# RE01_1500KB register map
Vendor: Renesas Electronics Corporation; Series: RE01_1500KB; File version: 1.20
CPU: CM0PLUS r0p1, little endian, MPU, no FPU, VTOR, 2 interrupt priority bits
Registers are 8-bit, read-write, reset 0x0 unless marked. A register's access mark holds for its fields unless they carry their own. Offsets are from the block's base; [hi:lo] are bit positions; lines under a group give offsets from that group; {n}, {i} and the like mark numbered series; 'fields as' and 'values as' point back to an identical list; <NAME> marks a mode.

## S14AD — 14bit A/D Converter
Base 0x4005C000
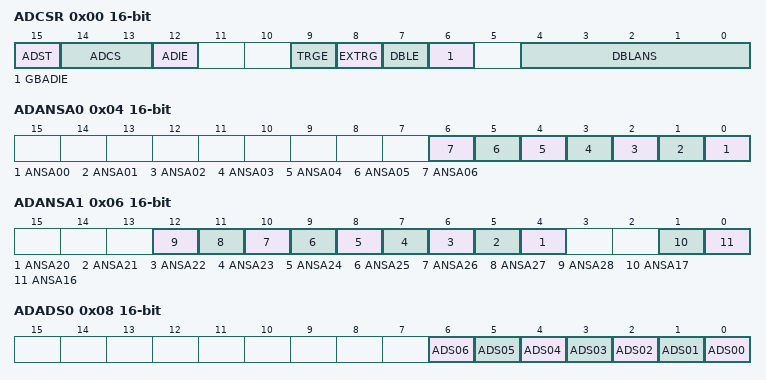
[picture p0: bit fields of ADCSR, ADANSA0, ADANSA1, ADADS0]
0x00 ADCSR 16-bit — A/D Control Register
  [15] ADST — A/D Conversion Start
    0=Stops A/D conversion process; 1=Starts A/D conversion process
  [14:13] ADCS — Scan Mode Select
    0=Single scan mode; 1=Group scan mode; 2=Continuous scan mode; 3=Setting prohibited
  [12] ADIE
  [9] TRGE — Trigger Start Enable
    0=Disables A/D conversion to be started by the synchronous or asynchronous trigger; 1=Enables A/D conversion to be started by the synchronous or asynchronous trigger
  [8] EXTRG — Trigger Select
    0=A/D conversion is started by the synchronous trigger (TMR,ELC); 1=A/D conversion is started by the asynchronous trigger (ADTRG0)
  [7] DBLE — Double Trigger Mode Select
    0=Double trigger mode non-selection; 1=Double trigger mode selection
  [6] GBADIE — Group B Scan End Interrupt Enable
    0=Disables ADC140_GBADI interrupt generation upon group B scan completion; 1=Enables ADC140_GBADI interrupt generation upon group B scan completion
  [4:0] DBLANS — Double Trigger Channel SelectThese bits select one analog input channel for double triggered operation. The setting is only effective while double trigger mode is selected.
0x04 ADANSA0 16-bit — A/D Channel Select Register A0
  [n] ANSA{n:02} (n=0..6) — AN{n:03} Select
    0=AN{n:03} is not subjected to conversion; 1=AN{n:03} is subjected to conversion
0x06 ADANSA1 16-bit — A/D Channel Select Register A1
  [n-16] ANSA{n} (n=20..28) — AN{n:04} Select
    0=AN{n:04} is not subjected to conversion; 1=AN{n:04} is subjected to conversion
  [1] ANSA17 — AN0017 Select
    0=AN0017 is not subjected to conversion; 1=AN0017 is subjected to conversion
  [0] ANSA16 — AN0016 Select
    0=AN0016 is not subjected to conversion; 1=AN0016 is subjected to conversion
0x08 ADADS0 16-bit — A/D-Converted Value Addition/Average Channel Select Register 0
  [n] ADS{n:02} (n=0..6) — A/D-Converted Value Addition/Average Channel AN{n:03} Select
    0=AN{n:03} is not selected; 1=AN{n:03} is selected
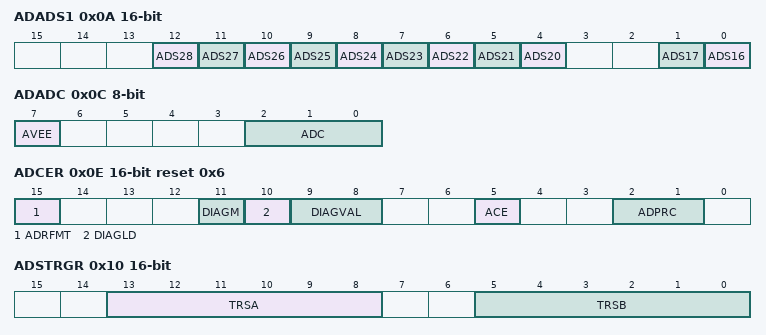
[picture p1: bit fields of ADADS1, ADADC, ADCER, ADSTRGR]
0x0A ADADS1 16-bit — A/D-Converted Value Addition/Average Channel Select Register 1
  [n-16] ADS{n} (n=20..28) — A/D-Converted Value Addition/Average Channel AN{n:03} Select
    0=AN{n:04} is not selected; 1=AN{n:04} is selected
  [1] ADS17 — A/D-Converted Value Addition/Average Channel AN017 Select
    0=AN0017 is not selected; 1=AN0017 is selected
  [0] ADS16 — A/D-Converted Value Addition/Average Channel AN016 Select
    0=AN0016 is not selected; 1=AN0016 is selected
0x0C ADADC — A/D-Converted Value Addition/Average Count Select Register
  [7] AVEE — Average Mode Enable
    0=Average mode is disabled*1; 1=Average mode is enabled*2
  [2:0] ADC — Addition frequency selection bit.
    0=1-time conversion (no addition; same as normal conversion); 1=2-time conversion (addition once); 3=4-time conversion (addition three times); 5=16-time conversion (addition 15 times), can not be set when selecting 14-bit accuracy; other=others (Setting prohibited)
0x0E ADCER 16-bit reset 0x6 — A/D Control Extended Register
  [15] ADRFMT — A/D Data Register Format Select
    0=Flush-right is selected for the A/D data register format; 1=Flush-left is selected for the A/D data register format
  [11] DIAGM — Self-Diagnosis Enable
    0=Disables self-diagnosis of A/D converter; 1=Enables self-diagnosis of A/D converter
  [10] DIAGLD — Self-Diagnosis Mode Select
    0=Rotation mode for self-diagnosis voltage; 1=Fixed mode for self-diagnosis voltage
  [9:8] DIAGVAL — Self-Diagnosis Conversion Voltage Select
    0=When the self-diagnosis fixation mode is selected, it set prohibits it; 1=The self-diagnosis by using the voltage of 0V; 2=The self-diagnosis by using the voltage of reference supply x 1/2; 3=The self-diagnosis by using the voltage of the reference supply
  [5] ACE — A/D Data Register Automatic Clearing Enable
    0=Disables automatic clearing; 1=Enables automatic clearing
  [2:1] ADPRC — A/D Conversion Accuracy Specify
    0=A/D conversion is performed with 12-bit accuracy; 3=A/D conversion is performed with 14-bit accuracy; other=others (Setting prohibited)
0x10 ADSTRGR 16-bit — A/D Conversion Start Trigger Select Register
  [13:8] TRSA — A/D Conversion Start Trigger SelectSelect the A/D conversion start trigger in single scan mode and continuous mode. In group scan mode, the A/D conversion start trigger for group A is selected.
  [5:0] TRSB — A/D Conversion Start Trigger Select for Group BSelect the A/D conversion start trigger for group B in group scan mode.
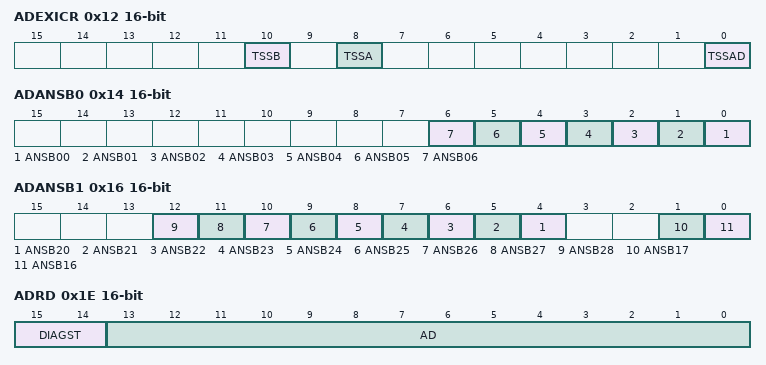
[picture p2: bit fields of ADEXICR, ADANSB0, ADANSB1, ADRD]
0x12 ADEXICR 16-bit — A/D Conversion Extended Input Control Register
  [10] TSSB — Temperature Sensor Output A/D Conversion Select for group B
    0=The temperature sensor output is not selected; 1=The temperature sensor output is selected
  [8] TSSA — Temperature Sensor Output A/D Conversion Select
    values as TSSB
  [0] TSSAD — Temperature Sensor Output A/D converted Value Addition/Average Mode Select
    0=Temperature sensor output A/D-converted value addition/average mode is not selected; 1=Temperature sensor output A/D-converted value addition/average mode is selected
0x14 ADANSB0 16-bit — A/D Channel Select Register B0
  [n] ANSB{n:02} (n=0..6) — AN{n:03} Select
    values as ADANSA0.ANSA00
0x16 ADANSB1 16-bit — A/D Channel Select Register B1
  [n-16] ANSB{n} (n=20..28) — AN{n:04} Select
    values as ADANSA1.ANSA20
  [1] ANSB17 — AN0017 Select
    values as ADANSA1.ANSA17
  [0] ANSB16 — AN0016 Select
    values as ADANSA1.ANSA16
0x18 ADDBLDR 16-bit ro — A/D Data Duplication Register
  [15:0] ADDBLDR — This is a 16-bit read-only register for storing the result of A/D conversion in response to the second trigger in double trigger mode.
0x1A ADTSDR 16-bit ro — A/D Temperature Sensor Data Register
  [15:0] ADTSDR — This is a 16-bit read-only register for storing the A/D conversion result of temperature sensor output.
0x1E ADRD 16-bit ro — A/D Self-Diagnosis Data Register
  [15:14] DIAGST — Self-Diagnosis StatusNote:Reference voltage refers to VREFH0.
    0=Self-diagnosis has never been executed since power-on; 1=Self-diagnosis using the voltage of 0 V has been executed; 2=Self-diagnosis using the voltage of reference power supply 1 x 1/2 has been executed; 3=Self-diagnosis using the voltage of reference power supply*1 has been executed
  [13:0] AD — A/D-converted value (right-justified)NOTE: Unused bits in the AD bit field are fixed 0
{0x20+2i} ADDR{i} (i=0..6) 16-bit ro — A/D Data Register {i}
  [15:0] ADDR — The ADDR register is a 16-bit read-only registers for storing the result of A/D conversion.
{0x20+2i} ADDR{i} (i=16..17) 16-bit ro — A/D Data Register {i}
  fields as ADDR0
{0x20+2i} ADDR{i} (i=20..28) 16-bit ro — A/D Data Register {i}
  fields as ADDR0
0x64 ADSCLKCR
  [0] SCLKEN
0x7A ADDISCR — A/D Disconnection Detection Control Register
  [4:0] ADNDIS — Disconnection Detection Assist SettingNOTE:When the A/D conversion of temperature sensor output is selected, ADNDIS[4:0] are set to 0Fh for discharging.
    0=Disconnection detection is disabled; 1=Setting prohibited; 2=2 cycle; {v}={v+1} cycle (v=3..15); 16=Disconnection detection is disabled; 17=Setting prohibited; 18=2 cycle; {v}={v-15} cycle (v=19..31)
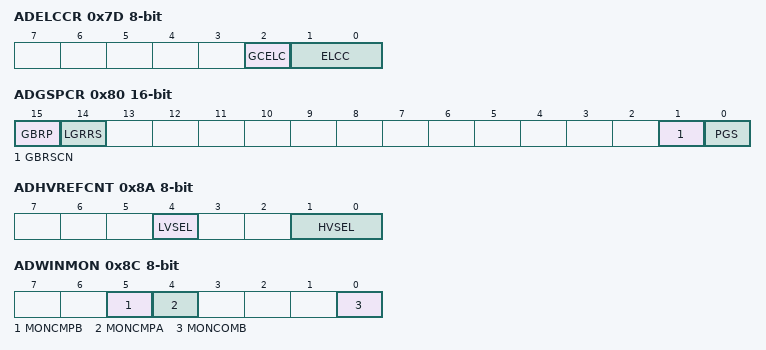
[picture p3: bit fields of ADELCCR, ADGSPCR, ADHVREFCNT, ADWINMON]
0x7D ADELCCR
  [2] GCELC — Group C Event Link Control
    0=No event is generated when group C scan completes in groupscan; 1=An event is generated when group C scan completes in groupscan
  [1:0] ELCC — Event Link Control
    0=An event is generated upon completion of scanning other; 1=An event is generated when group B scan completes in; other=others (An event is generated)
0x80 ADGSPCR 16-bit — A/D Group Scan Priority Control Register
  [15] GBRP — Single Scan Continuous Start(Enabled only when PGS = 1. Reserved when PGS = 0.)Note: When the GBRP bit has been set to 1, single scan is performed continuously for the lowest priority group regardless of the setting of the GBRSCN bit.
    0=Single scan is not continuously activated; 1=Single scan is continuously activated for the lowest priority group
  [14] LGRRS
  [1] GBRSCN — Low priority group Restart Setting(Enabled only when PGS = 1. Reserved when PGS = 0.)
    0=Scanning for low priority group is not restarted after having been discontinued due to priority control; 1=Scanning for low priority group is restarted after having been discontinued due to priority control
  [0] PGS — Group priority control setting bit.Note: When the PGS bit is to be set to 1, the ADCSR.ADCS[1:0] bits must be set to 01b (group scan mode). If the bits are set to any other values, proper operation is not guaranteed.
    0=Operation is without priority control; 1=Operation is with priority control
0x8A ADHVREFCNT — A/D High-Potential/Low-Potential Reference Voltage Control Register
  [4] LVSEL — Low-Potential Reference Voltage Select
    0=Select AVSS0 as the low-potential reference voltage; 1=Select VREFL0 as the low-potential reference voltage
  [1:0] HVSEL — High-Potential Reference Voltage Select
    0=Select AVCC0 as the high-potential reference voltage; 1=Select VREFH0 as the high-potential reference voltage; other=others (Setting prohibited)
0x8C ADWINMON ro — A/D Compare Function Window A/B Status Monitor Register
  [5] MONCMPB — Comparison Result Monitor B
    0=Window B comparison conditions are not met; 1=Window B comparison conditions are met
  [4] MONCMPA — Comparison Result Monitor A
    0=Window A comparison conditions are not met; 1=Window A comparison conditions are met
  [0] MONCOMB — Combination result monitorThis bit indicates the combination result.This bit is valid when both window A operation and window B operation are enabled.
    0=Window A / window B composite conditions are not met; 1=Window A / window B composite conditions are met
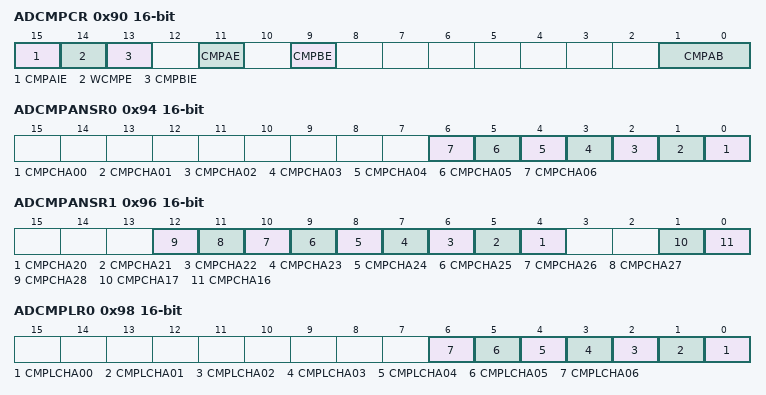
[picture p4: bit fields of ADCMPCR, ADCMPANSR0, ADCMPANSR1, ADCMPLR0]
0x90 ADCMPCR 16-bit — A/D Compare Function Control Register
  [15] CMPAIE — Compare A Interrupt Enable
    0=ADC140_CMPAI interrupt is disabled when comparison conditions (window A) are met; 1=ADC140_CMPAI interrupt is enabled when comparison conditions (window A) are met
  [14] WCMPE — Window Function Setting
    0=Window function is disabled. Window A and window B operate as a comparator to comparator the single value on the lower side with the A/D conversion result.; 1=Window function is enabled. Window A and window B operate as a comparator to comparator the two values on the upper and lower sides with the A/D conversion result.
  [13] CMPBIE — Compare B Interrupt Enable
    0=ADC140_CMPBI interrupt is disabled when comparison conditions (window B) are met; 1=ADC140_CMPBI interrupt is enabled when comparison conditions (window B) are met
  [11] CMPAE — Compare Window A Operation Enable
    0=Compare window A operation is disabled. ADC140_WCMPM and ADC140_WCMPUM outputs are disabled.; 1=Compare window A operation is enabled
  [9] CMPBE — Compare Window B Operation Enable
    0=Compare window B operation is disabled. ADC140_WCMPM and ADC140_WCMPUM outputs are disabled.; 1=Compare window B operation is enabled
  [1:0] CMPAB — Window A/B Composite Conditions SettingNOTE: These bits are valid when both window A and window B are enabled (CMPAE = 1 and CMPBE = 1).
    0=ADC140_WCMPM is output when window A comparison conditions are met OR window B comparison conditions are met. ADC140_WCMPUM is output in other cases.; 1=ADC140_WCMPM is output when window A comparison conditions are met EXOR window B comparison conditions are met. ADC140_WCMPUM is output in other cases.; 2=ADC140_WCMPM is output when window A comparison conditions are met and window B comparison conditions are met. ADC140_WCMPUM is output in other cases.; 3=Setting prohibited
0x92 ADCMPANSER — A/D Compare Function Window A Extended Input Select Register
  [0] CMPTSA — Temperature sensor output Compare selection bit.
    0=Excludes the temperature sensor output from the compare window A target range; 1=Includes the temperature sensor output in the compare window A target range
0x93 ADCMPLER — A/D Compare Function Window A Extended Input Comparison Condition Setting Register
  [0] CMPLTSA — Compare Window A Temperature Sensor Output Comparison Condition Select
    0=ADCMPDR0 register value > A/D-converted value(ADCMPCR.WCMPE=0) / AD-converted value < ADCMPDR0 register value or A/D-converted value > ADCMPDR1 register value(ADCMPCR.WCMPE=1); 1=ADCMPDR0 register value < A/D-converted value(ADCMPCR.WCMPE=0) / ADCMPDR0 register value < A/D-converted value < ADCMPDR1 register value(ADCMPCR.WCMPE=1)
0x94 ADCMPANSR0 16-bit — A/D Compare Function Window A Channel Select Register 0
  [n] CMPCHA{n:02} (n=0..6) — AN{n:03} Select
    0=Excludes AN{n:03} from the compare window A target range; 1=Includes AN{n:03} from the compare window A target range
0x96 ADCMPANSR1 16-bit — A/D Compare Function Window A Channel Select Register 1
  [n-16] CMPCHA{n} (n=20..28) — AN{n:04} Select
    0=Excludes AN{n:04} from the compare window A target range; 1=Includes AN{n:04} from the compare window A target range
  [1] CMPCHA17 — AN0017 Select
    0=Excludes AN0017 from the compare window A target range; 1=Includes AN0017 from the compare window A target range
  [0] CMPCHA16 — AN0016 Select
    0=Excludes AN0016 from the compare window A target range; 1=Includes AN0016 from the compare window A target range
0x98 ADCMPLR0 16-bit — A/D Compare Function Window A Comparison Condition Setting Register 0
  [all] fields
    0=ADCMPDR0 value > A/D converted value (ADCMPCR.WCMPE=0) / A/D converted value < ADCMPDR0 value or, ADCMPDR1 value < A/D converted value (ADCMPCR.WCMPE=1); 1=ADCMPDR0 value < A/D converted value (ADCMPCR.WCMPE=0) / A/DCMPDR0 value < A/D converted value < ADCMPDR1 value (ADCMPCR.WCMPE=1)
  [n] CMPLCHA{n:02} (n=0..6) — Comparison condition of AN{n:03}
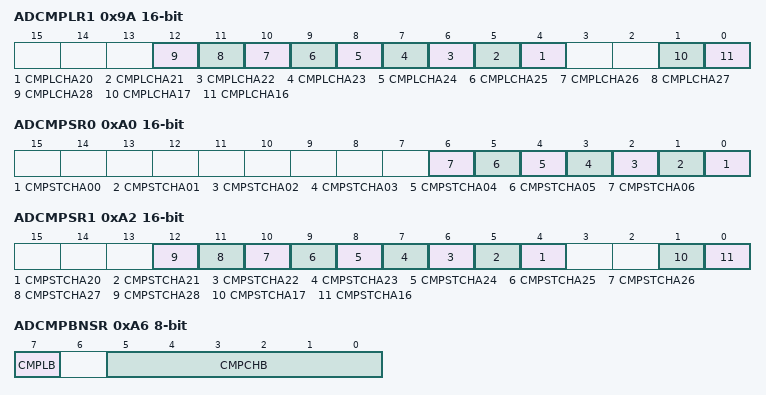
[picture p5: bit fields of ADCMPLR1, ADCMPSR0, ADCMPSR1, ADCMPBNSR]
0x9A ADCMPLR1 16-bit — A/D Compare Function Window A Comparison Condition Setting Register 1
  [all] fields
    values as the fields of ADCMPLR0
  [n-16] CMPLCHA{n} (n=20..28) — Comparison condition of AN{n:04}
  [1] CMPLCHA17 — Comparison condition of AN0017
  [0] CMPLCHA16 — Comparison condition of AN0016
0x9C ADCMPDR0 16-bit — A/D Compare Function Window A Lower-Side Level Setting Register
  [15:0] ADCMPDR0 — The ADCMPDR0 register sets the reference data when the compare window A function is used. ADCMPDR0 sets the lower-side level of window A.
0x9E ADCMPDR1 16-bit — A/D Compare Function Window A Upper-Side Level Setting Register
  [15:0] ADCMPDR1 — The ADCMPDR1 register sets the reference data when the compare window A function is used. ADCMPDR1 sets the upper-side level of window A..
0xA0 ADCMPSR0 16-bit — A/D Compare Function Window A Channel Status Register 0
  [all] fields
    0=Comparison conditions are not met; 1=Comparison conditions are met
  [n] CMPSTCHA{n:02} (n=0..6) — Compare window A flag of AN{n:03}
0xA2 ADCMPSR1 16-bit — A/D Compare Function Window A Channel Status Register 1
  [all] fields
    values as the fields of ADCMPSR0
  [n-16] CMPSTCHA{n} (n=20..28) — Compare window A flag of AN{n:04}
  [1] CMPSTCHA17 — Compare window A flag of AN0017
  [0] CMPSTCHA16 — Compare window A flag of AN0016
0xA4 ADCMPSER — A/D Compare Function Window A Extended Input Channel Status Register
  [0] CMPSTTSA — Compare Window A Temperature Sensor Output Compare Flag When window A operation is enabled (ADCMPCR.CMPAE = 1b), this bit indicates the temperature sensor output comparison result.
    values as the fields of ADCMPSR0
0xA6 ADCMPBNSR — A/D Compare Function Window B Channel Selection Register
  [7] CMPLB — Compare window B Compare condition setting bit.
    0=CMPLLB value > A/D converted value (ADCMPCR.WCMPE=0) / A/D converted value < CMPLLB value or CMPULB value > A/D converted value (ADCMPCR.WCMPE=1); 1=CMPLLB value < A/D converted value(ADCMPCR.WCMPE=0) / CMPLLB value < A/D converted value < CMPULB value (ADCMPCR.WCMPE=1)
  [5:0] CMPCHB — Compare window B channel selection bit.The channel that compares it on the condition of compare window B is selected.
    {v}=AN{v:03} (v=0..6); {v}=AN{v+9:03} (v=7..13); {v}=AN{v+9:03} (v=16..19); 32=Temperature sensor; 63=No channel is selected; other=others (Setting prohibited)
0xA8 ADWINLLB 16-bit — A/D Compare Function Window B Lower-Side Level Setting Register
  [15:0] ADWINLLB — This register is used to compare A window function is used to set the lower level of the window B.
0xAA ADWINULB 16-bit — A/D Compare Function Window B Upper-Side Level Setting Register
  [15:0] ADWINULB — This register is used to compare A window function is used to set the higher level of the window B.
0xAC ADCMPBSR — A/D Compare Function Window B Status Register
  [0] CMPSTB — Compare window B flag.It is a status flag that shows the comparative result of CH (AN000-AN019 and temperature sensor) made the object of window B relation condition.
    values as the fields of ADCMPSR0
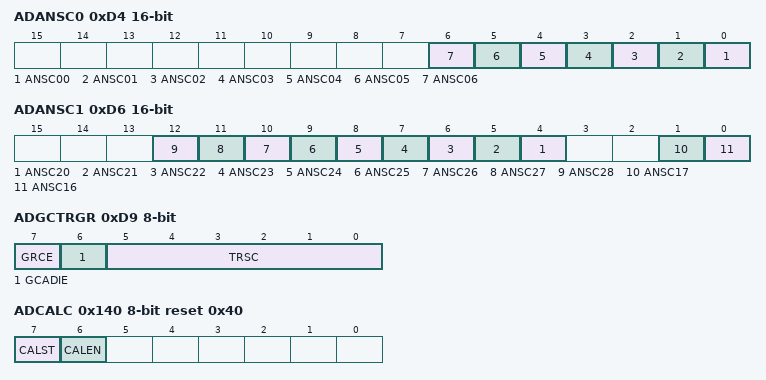
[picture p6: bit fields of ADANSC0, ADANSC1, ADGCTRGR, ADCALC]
0xD4 ADANSC0 16-bit — A/D Channel Select Register C0
  [n] ANSC{n:02} (n=0..6) — AN{n:03} Select
    values as ADANSA0.ANSA00
0xD6 ADANSC1 16-bit — A/D Channel Select Register C1
  [n-16] ANSC{n} (n=20..28) — AN{n:04} Select
    values as ADANSA1.ANSA20
  [1] ANSC17 — AN0017 Select
    values as ADANSA1.ANSA17
  [0] ANSC16 — AN0016 Select
    values as ADANSA1.ANSA16
0xD8 ADGCEXCR
  [0] TSSC
0xD9 ADGCTRGR
  [7] GRCE
  [6] GCADIE
  [5:0] TRSC
    63=111111; 11=001011
0xDD ADSSTRL reset 0xF — A/D Sampling State Register L
  [7:0] SST range 0x05..0xFF — Sampling Time Setting (AN016-AN019)
0xDE ADSSTRT reset 0xF — A/D Sampling State Register T
  [7:0] SST range 0x05..0xFF — Sampling Time Setting (temperature sensor output)
{0xE0+i} ADSSTR{i} (i=0..6) reset 0xF — A/D Sampling State Register {i}
  [7:0] SST range 0x05..0xFF — Sampling time setting
0x140 ADCALC reset 0x40
  [7] CALST, [6] CALEN
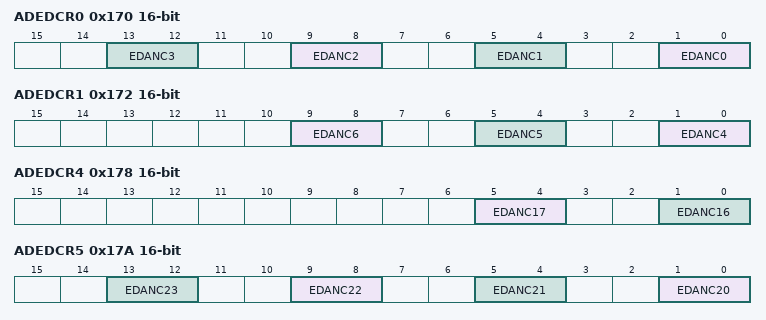
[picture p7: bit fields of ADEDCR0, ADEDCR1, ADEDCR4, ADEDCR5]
0x170 ADEDCR0 16-bit
  [all] fields
    0=00; 1=01; 2=10; 3=11
  [4n+1:4n] EDANC{n} (n=0..3)
0x172 ADEDCR1 16-bit
  [all] fields
    0=00; 1=01; 2=10; 3=11
  [9:8] EDANC6
  [5:4] EDANC5
  [1:0] EDANC4
0x178 ADEDCR4 16-bit
  [5:4] EDANC17
    0=00; 1=01; 2=10; 3=11
  [1:0] EDANC16
    0=00; 1=01; 2=10; 3=11
0x17A ADEDCR5 16-bit
  [all] fields
    0=00; 1=01; 2=10; 3=11
  [4n-79:4n-80] EDANC{n} (n=20..23)
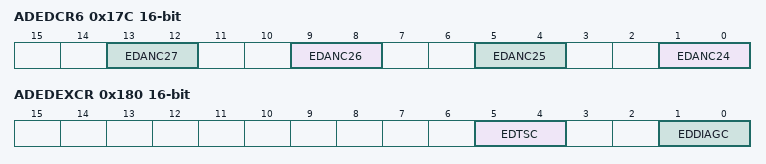
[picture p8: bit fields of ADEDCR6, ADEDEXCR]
0x17C ADEDCR6 16-bit
  [all] fields
    0=00; 1=01; 2=10; 3=11
  [4n-95:4n-96] EDANC{n} (n=24..27)
0x17E ADEDCR7 16-bit
  [1:0] EDANC28
    0=00; 1=01; 2=10; 3=11
0x180 ADEDEXCR 16-bit
  [5:4] EDTSC
    0=00; 1=01; 2=10; 3=Setting prohibited
  [1:0] EDDIAGC
    0=00; 1=01; 2=:-; 3=Setting prohibited
0x182 ADEDDMY0 16-bit
  [13:0] EDDMY0
0x184 ADEDDMY1 16-bit
  [13:0] EDDMY1
0x1C0 ADSCS0
  [4:0] SCS00
0x1C1 ADSCS1 reset 0x1
  [4:0] SCS01
0x1C2 ADSCS2 reset 0x2
  [4:0] SCS02
0x1C3 ADSCS3 reset 0x3
  [4:0] SCS03
0x1C4 ADSCS4 reset 0x4
  [4:0] SCS04
0x1C5 ADSCS5 reset 0x5
  [4:0] SCS05
0x1C6 ADSCS6 reset 0x6
  [4:0] SCS06
0x1D0 ADSCS16 reset 0x10
  [4:0] SCS07
0x1D1 ADSCS17 reset 0x11
  [4:0] SCS08
0x1D4 ADSCS20 reset 0x14
  [4:0] SCS11
0x1D5 ADSCS21 reset 0x15
  [4:0] SCS12
0x1D6 ADSCS22 reset 0x16
  [4:0] SCS13
0x1D7 ADSCS23 reset 0x17
  [4:0] SCS14
0x1D8 ADSCS24 reset 0x18
  [4:0] SCS15
0x1D9 ADSCS25 reset 0x19
  [4:0] SCS16
0x1DA ADSCS26 reset 0x1A
  [4:0] SCS17
0x1DB ADSCS27 reset 0x1B
  [4:0] SCS18
0x1DC ADSCS28 reset 0x1C
  [4:0] SCS19
